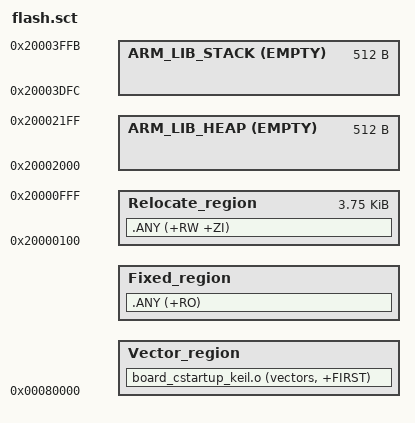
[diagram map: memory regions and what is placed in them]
; *------------------------------------------------------------------------------
; *      Linker scatter for running in internal SRAM on the AT91SAM2U4
; *----------------------------------------------------------------------------*/

; /* vector is put at very begin adress of SRAM0, the preserved size is 0x100 */
Load_region 0x80000 0x20000
{
    ; Flash 128K
    Vector_region 0x80000
    {
        board_cstartup_keil.o (vectors, +FIRST)
    }
    Fixed_region +0
    {
        .ANY (+RO)
    }
    ; SRAM0 16K
    Relocate_region 0x20000100 (0x1000-0x100)
    {
        .ANY (+RW +ZI)
    }
    ; Configure Stack and Heap
    ARM_LIB_HEAP 0x20002000 EMPTY 0x200
    {
    }

    ARM_LIB_STACK 0x20003FFC EMPTY -0x200
    {
    }
}

